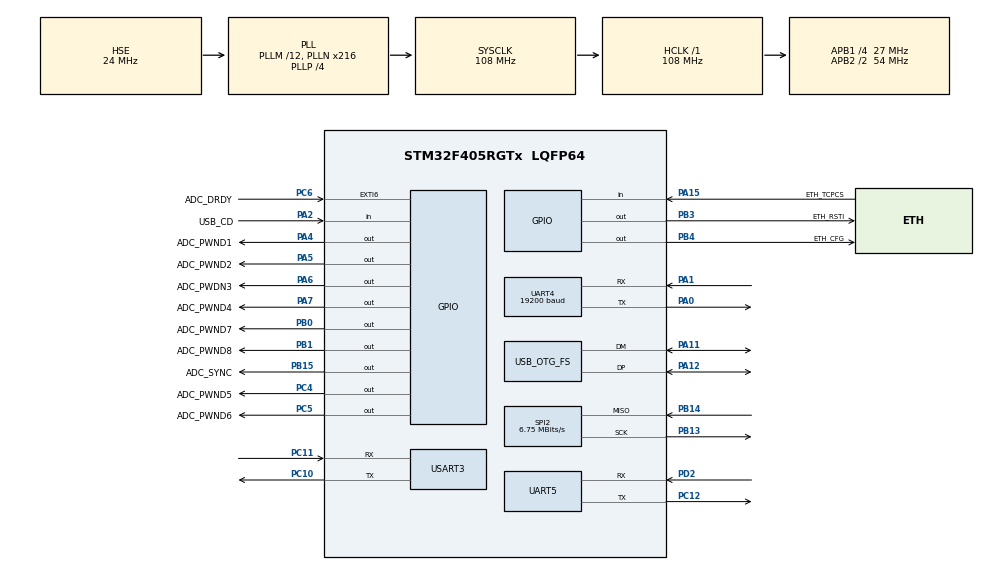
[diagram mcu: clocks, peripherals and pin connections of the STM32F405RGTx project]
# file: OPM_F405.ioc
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Dma.Request0=UART4_RX
Dma.Request1=UART4_TX
Dma.Request2=SPI2_RX
Dma.Request3=USART3_RX
Dma.Request4=UART5_RX
Dma.SPI2_RX.2.Direction=DMA_PERIPH_TO_MEMORY
Dma.SPI2_RX.2.FIFOMode=DMA_FIFOMODE_DISABLE
Dma.SPI2_RX.2.Instance=DMA1_Stream3
Dma.SPI2_RX.2.MemDataAlignment=DMA_MDATAALIGN_BYTE
Dma.SPI2_RX.2.MemInc=DMA_MINC_ENABLE
Dma.SPI2_RX.2.Mode=DMA_NORMAL
Dma.SPI2_RX.2.PeriphDataAlignment=DMA_PDATAALIGN_BYTE
Dma.SPI2_RX.2.PeriphInc=DMA_PINC_DISABLE
Dma.SPI2_RX.2.Priority=DMA_PRIORITY_LOW
Dma.UART4_RX.0.Direction=DMA_PERIPH_TO_MEMORY
Dma.UART4_RX.0.FIFOMode=DMA_FIFOMODE_DISABLE
Dma.UART4_RX.0.Instance=DMA1_Stream2
Dma.UART4_RX.0.MemDataAlignment=DMA_MDATAALIGN_BYTE
Dma.UART4_RX.0.MemInc=DMA_MINC_ENABLE
Dma.UART4_RX.0.Mode=DMA_NORMAL
Dma.UART4_RX.0.PeriphDataAlignment=DMA_PDATAALIGN_BYTE
Dma.UART4_RX.0.PeriphInc=DMA_PINC_DISABLE
Dma.UART4_RX.0.Priority=DMA_PRIORITY_LOW
Dma.UART4_TX.1.Direction=DMA_MEMORY_TO_PERIPH
Dma.UART4_TX.1.FIFOMode=DMA_FIFOMODE_DISABLE
Dma.UART4_TX.1.Instance=DMA1_Stream4
Dma.UART4_TX.1.MemDataAlignment=DMA_MDATAALIGN_BYTE
Dma.UART4_TX.1.MemInc=DMA_MINC_ENABLE
Dma.UART4_TX.1.Mode=DMA_NORMAL
Dma.UART4_TX.1.PeriphDataAlignment=DMA_PDATAALIGN_BYTE
Dma.UART4_TX.1.PeriphInc=DMA_PINC_DISABLE
Dma.UART4_TX.1.Priority=DMA_PRIORITY_LOW
Dma.UART5_RX.4.Direction=DMA_PERIPH_TO_MEMORY
Dma.UART5_RX.4.FIFOMode=DMA_FIFOMODE_DISABLE
Dma.UART5_RX.4.Instance=DMA1_Stream0
Dma.UART5_RX.4.MemDataAlignment=DMA_MDATAALIGN_BYTE
Dma.UART5_RX.4.MemInc=DMA_MINC_ENABLE
Dma.UART5_RX.4.Mode=DMA_NORMAL
Dma.UART5_RX.4.PeriphDataAlignment=DMA_PDATAALIGN_BYTE
Dma.UART5_RX.4.PeriphInc=DMA_PINC_DISABLE
Dma.UART5_RX.4.Priority=DMA_PRIORITY_LOW
Dma.USART3_RX.3.Direction=DMA_PERIPH_TO_MEMORY
Dma.USART3_RX.3.FIFOMode=DMA_FIFOMODE_DISABLE
Dma.USART3_RX.3.Instance=DMA1_Stream1
Dma.USART3_RX.3.MemDataAlignment=DMA_MDATAALIGN_BYTE
Dma.USART3_RX.3.MemInc=DMA_MINC_ENABLE
Dma.USART3_RX.3.Mode=DMA_NORMAL
Dma.USART3_RX.3.PeriphDataAlignment=DMA_PDATAALIGN_BYTE
Dma.USART3_RX.3.PeriphInc=DMA_PINC_DISABLE
Dma.USART3_RX.3.Priority=DMA_PRIORITY_LOW
FREERTOS.Tasks01=defaultTask,24,128,StartDefaultTask,Default,NULL,Dynamic,NULL,NULL
Mcu.Family=STM32F4
Mcu.Name=STM32F405RGTx
Mcu.Package=LQFP64
NVIC.DMA1_Stream0_IRQn=true\:5\:0\:false\:false\:true\:true\:false\:true\:true
NVIC.DMA1_Stream1_IRQn=true\:5\:0\:false\:false\:true\:true\:false\:true\:true
NVIC.DMA1_Stream2_IRQn=true\:5\:0\:false\:false\:true\:true\:false\:true\:true
NVIC.DMA1_Stream3_IRQn=true\:5\:0\:false\:false\:true\:true\:false\:true\:true
NVIC.DMA1_Stream4_IRQn=true\:5\:0\:false\:false\:true\:true\:false\:true\:true
NVIC.EXTI9_5_IRQn=true\:5\:0\:false\:false\:true\:true\:true\:true\:true
NVIC.PriorityGroup=NVIC_PRIORITYGROUP_4
NVIC.TIM1_UP_TIM10_IRQn=true\:15\:0\:false\:false\:true\:false\:false\:true\:true
NVIC.TIM8_TRG_COM_TIM14_IRQn=true\:5\:0\:false\:false\:true\:true\:true\:false\:true
NVIC.TimeBase=TIM1_UP_TIM10_IRQn
NVIC.TimeBaseIP=TIM1
NVIC.UART4_IRQn=true\:5\:0\:false\:false\:true\:true\:true\:true\:true
NVIC.UART5_IRQn=true\:5\:0\:false\:false\:true\:true\:true\:true\:true
NVIC.USART3_IRQn=true\:5\:0\:false\:false\:true\:true\:true\:true\:true
PA0-WKUP.Mode=Asynchronous
PA0-WKUP.Signal=UART4_TX
PA1.Mode=Asynchronous
PA1.Signal=UART4_RX
PA11.Mode=Device_Only
PA11.Signal=USB_OTG_FS_DM
PA12.Mode=Device_Only
PA12.Signal=USB_OTG_FS_DP
PA13.Mode=Serial_Wire
PA13.Signal=SYS_JTMS-SWDIO
PA14.Mode=Serial_Wire
PA14.Signal=SYS_JTCK-SWCLK
PA15.GPIO_Label=ETH_TCPCS
PA15.Signal=GPIO_Input
PA2.GPIO_Label=USB_CD
PA2.Signal=GPIO_Input
PA4.GPIO_Label=ADC_PWND1
PA4.Signal=GPIO_Output
PA5.GPIO_Label=ADC_PWND2
PA5.Signal=GPIO_Output
PA6.GPIO_Label=ADC_PWDN3
PA6.Signal=GPIO_Output
PA7.GPIO_Label=ADC_PWND4
PA7.Signal=GPIO_Output
PB0.GPIO_Label=ADC_PWND7
PB0.Signal=GPIO_Output
PB1.GPIO_Label=ADC_PWND8
PB1.Signal=GPIO_Output
PB13.Mode=RX_Only_Simplex_Unidirect_Master
PB13.Signal=SPI2_SCK
PB14.Mode=RX_Only_Simplex_Unidirect_Master
PB14.Signal=SPI2_MISO
PB15.GPIO_Label=ADC_SYNC
PB15.Signal=GPIO_Output
PB3.GPIO_Label=ETH_RSTI
PB3.Signal=GPIO_Output
PB4.GPIO_Label=ETH_CFG
PB4.Signal=GPIO_Output
PC10.Mode=Asynchronous
PC10.Signal=USART3_TX
PC11.Mode=Asynchronous
PC11.Signal=USART3_RX
PC12.Mode=Asynchronous
PC12.Signal=UART5_TX
PC4.GPIO_Label=ADC_PWND5
PC4.Signal=GPIO_Output
PC5.GPIO_Label=ADC_PWND6
PC5.Signal=GPIO_Output
PC6.GPIO_Label=ADC_DRDY
PC6.GPIO_ModeDefaultEXTI=GPIO_MODE_IT_FALLING
PC6.GPIO_PuPd=GPIO_NOPULL
PC6.Signal=GPXTI6
PD2.Mode=Asynchronous
PD2.Signal=UART5_RX
PH0-OSC_IN.Mode=HSE-External-Clock-Source
PH0-OSC_IN.Signal=RCC_OSC_IN
PH1-OSC_OUT.Mode=HSE-External-Clock-Source
PH1-OSC_OUT.Signal=RCC_OSC_OUT
ProjectManager.HeapSize=0x200
ProjectManager.StackSize=0x400
ProjectManager.TargetToolchain=MDK-ARM V5.32
RCC.48MHZClocksFreq_Value=48000000
RCC.AHBFreq_Value=108000000
RCC.APB1CLKDivider=RCC_HCLK_DIV4
RCC.APB1Freq_Value=27000000
RCC.APB1TimFreq_Value=54000000
RCC.APB2CLKDivider=RCC_HCLK_DIV2
RCC.APB2Freq_Value=54000000
RCC.APB2TimFreq_Value=108000000
RCC.CortexFreq_Value=108000000
RCC.HCLKFreq_Value=108000000
RCC.HSE_VALUE=24000000
RCC.HSI_VALUE=16000000
RCC.LSE_VALUE=32768
RCC.PLLM=12
RCC.PLLN=216
RCC.PLLP=RCC_PLLP_DIV4
RCC.PLLQ=9
RCC.SYSCLKFreq_VALUE=108000000
RCC.SYSCLKSource=RCC_SYSCLKSOURCE_PLLCLK
RCC.VCOOutputFreq_Value=432000000
SPI2.BaudRatePrescaler=SPI_BAUDRATEPRESCALER_4
SPI2.CalculateBaudRate=6.75 MBits/s
SPI2.Direction=SPI_DIRECTION_2LINES_RXONLY
SPI2.Mode=SPI_MODE_MASTER
SPI2.VirtualType=VM_MASTER
TIM14.AutoReloadPreload=TIM_AUTORELOAD_PRELOAD_ENABLE
TIM14.Channel=TIM_CHANNEL_1
TIM14.Period=3000-1
TIM14.Prescaler=72-1
TIM2.TIM_MasterSlaveMode=TIM_MASTERSLAVEMODE_DISABLE
UART4.BaudRate=19200
UART4.VirtualMode=Asynchronous
UART5.VirtualMode=Asynchronous
USART3.VirtualMode=VM_ASYNC
USB_OTG_FS.VirtualMode=Device_Only
VP_FREERTOS_VS_CMSIS_V2.Mode=CMSIS_V2
VP_SYS_VS_tim1.Mode=TIM1
VP_TIM14_VS_ClockSourceINT.Mode=Enable_Timer
VP_TIM14_VS_no_output1.Mode=PWM Generation1 No Output
VP_TIM2_VS_ClockSourceINT.Mode=Internal
board=custom

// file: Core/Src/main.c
/* USER CODE BEGIN Header */
/**
  ******************************************************************************
  * @file           : main.c
  * @brief          : Main program body
  ******************************************************************************
  * @attention
  *
  * Copyright (c) 2026 STMicroelectronics.
  * All rights reserved.
  *
  * This software is licensed under terms that can be found in the LICENSE file
  * in the root directory of this software component.
  * If no LICENSE file comes with this software, it is provided AS-IS.
  *
  ******************************************************************************
  */
/* USER CODE END Header */
#include "main.h"
#include "cmsis_os.h"

/* USER CODE BEGIN Includes */
#include "ADC_Task.h"
#include "UART_Task.h"

/* USER CODE END Includes */

SPI_HandleTypeDef hspi2;
DMA_HandleTypeDef hdma_spi2_rx;

TIM_HandleTypeDef htim2;
TIM_HandleTypeDef htim14;

UART_HandleTypeDef huart4;
UART_HandleTypeDef huart5;
UART_HandleTypeDef huart3;
DMA_HandleTypeDef hdma_uart4_rx;
DMA_HandleTypeDef hdma_uart4_tx;
DMA_HandleTypeDef hdma_uart5_rx;
DMA_HandleTypeDef hdma_usart3_rx;

PCD_HandleTypeDef hpcd_USB_OTG_FS;

/* Definitions for defaultTask */
osThreadId_t defaultTaskHandle;
const osThreadAttr_t defaultTask_attributes = {
  .name = "defaultTask",
  .stack_size = 128 * 4,
  .priority = (osPriority_t) osPriorityNormal,
};

void SystemClock_Config(void);
static void MX_GPIO_Init(void);
static void MX_DMA_Init(void);
static void MX_SPI2_Init(void);
static void MX_UART4_Init(void);
static void MX_UART5_Init(void);
static void MX_USART3_UART_Init(void);
static void MX_USB_OTG_FS_PCD_Init(void);
static void MX_TIM14_Init(void);
static void MX_TIM2_Init(void);
void StartDefaultTask(void *argument);

int main(void)
{

  /* MCU Configuration--------------------------------------------------------*/

  /* Reset of all peripherals, Initializes the Flash interface and the Systick. */
  HAL_Init();

  /* Configure the system clock */
  SystemClock_Config();

  /* Initialize all configured peripherals */
  MX_GPIO_Init();
  MX_DMA_Init();
  MX_SPI2_Init();
  MX_UART4_Init();
  MX_UART5_Init();
  MX_USART3_UART_Init();
  MX_USB_OTG_FS_PCD_Init();
  MX_TIM14_Init();
  MX_TIM2_Init();

  /* Init scheduler */
  osKernelInitialize();

  /* Create the thread(s) */
  /* creation of defaultTask */
  defaultTaskHandle = osThreadNew(StartDefaultTask, NULL, &defaultTask_attributes);

  /* USER CODE BEGIN RTOS_THREADS */
  /* add threads, ... */
	adc_task_init();
	hmi_task_init();
	opm_task_init();
  /* USER CODE END RTOS_THREADS */

  /* Start scheduler */
  osKernelStart();

  /* We should never get here as control is now taken by the scheduler */

  /* Infinite loop */
  while (1)
  {

  }
}

void SystemClock_Config(void)
{
  RCC_OscInitTypeDef RCC_OscInitStruct = {0};
  RCC_ClkInitTypeDef RCC_ClkInitStruct = {0};

  /** Configure the main internal regulator output voltage
  */
  __HAL_RCC_PWR_CLK_ENABLE();
  __HAL_PWR_VOLTAGESCALING_CONFIG(PWR_REGULATOR_VOLTAGE_SCALE1);

  /** Initializes the RCC Oscillators according to the specified parameters
  * in the RCC_OscInitTypeDef structure.
  */
  RCC_OscInitStruct.OscillatorType = RCC_OSCILLATORTYPE_HSE;
  RCC_OscInitStruct.HSEState = RCC_HSE_BYPASS;
  RCC_OscInitStruct.PLL.PLLState = RCC_PLL_ON;
  RCC_OscInitStruct.PLL.PLLSource = RCC_PLLSOURCE_HSE;
  RCC_OscInitStruct.PLL.PLLM = 12;
  RCC_OscInitStruct.PLL.PLLN = 216;
  RCC_OscInitStruct.PLL.PLLP = RCC_PLLP_DIV4;
  RCC_OscInitStruct.PLL.PLLQ = 9;
  if (HAL_RCC_OscConfig(&RCC_OscInitStruct) != HAL_OK)
  {
    Error_Handler();
  }

  /** Initializes the CPU, AHB and APB buses clocks
  */
  RCC_ClkInitStruct.ClockType = RCC_CLOCKTYPE_HCLK|RCC_CLOCKTYPE_SYSCLK
                              |RCC_CLOCKTYPE_PCLK1|RCC_CLOCKTYPE_PCLK2;
  RCC_ClkInitStruct.SYSCLKSource = RCC_SYSCLKSOURCE_PLLCLK;
  RCC_ClkInitStruct.AHBCLKDivider = RCC_SYSCLK_DIV1;
  RCC_ClkInitStruct.APB1CLKDivider = RCC_HCLK_DIV4;
  RCC_ClkInitStruct.APB2CLKDivider = RCC_HCLK_DIV2;

  if (HAL_RCC_ClockConfig(&RCC_ClkInitStruct, FLASH_LATENCY_3) != HAL_OK)
  {
    Error_Handler();
  }
}

static void MX_SPI2_Init(void)
{

  /* SPI2 parameter configuration*/
  hspi2.Instance = SPI2;
  hspi2.Init.Mode = SPI_MODE_MASTER;
  hspi2.Init.Direction = SPI_DIRECTION_2LINES_RXONLY;
  hspi2.Init.DataSize = SPI_DATASIZE_8BIT;
  hspi2.Init.CLKPolarity = SPI_POLARITY_LOW;
  hspi2.Init.CLKPhase = SPI_PHASE_1EDGE;
  hspi2.Init.NSS = SPI_NSS_SOFT;
  hspi2.Init.BaudRatePrescaler = SPI_BAUDRATEPRESCALER_4;
  hspi2.Init.FirstBit = SPI_FIRSTBIT_MSB;
  hspi2.Init.TIMode = SPI_TIMODE_DISABLE;
  hspi2.Init.CRCCalculation = SPI_CRCCALCULATION_DISABLE;
  hspi2.Init.CRCPolynomial = 10;
  if (HAL_SPI_Init(&hspi2) != HAL_OK)
  {
    Error_Handler();
  }

}

static void MX_TIM2_Init(void)
{

  TIM_ClockConfigTypeDef sClockSourceConfig = {0};
  TIM_MasterConfigTypeDef sMasterConfig = {0};

  htim2.Instance = TIM2;
  htim2.Init.Prescaler = 0;
  htim2.Init.CounterMode = TIM_COUNTERMODE_UP;
  htim2.Init.Period = 4294967295;
  htim2.Init.ClockDivision = TIM_CLOCKDIVISION_DIV1;
  htim2.Init.AutoReloadPreload = TIM_AUTORELOAD_PRELOAD_DISABLE;
  if (HAL_TIM_Base_Init(&htim2) != HAL_OK)
  {
    Error_Handler();
  }
  sClockSourceConfig.ClockSource = TIM_CLOCKSOURCE_INTERNAL;
  if (HAL_TIM_ConfigClockSource(&htim2, &sClockSourceConfig) != HAL_OK)
  {
    Error_Handler();
  }
  sMasterConfig.MasterOutputTrigger = TIM_TRGO_RESET;
  sMasterConfig.MasterSlaveMode = TIM_MASTERSLAVEMODE_DISABLE;
  if (HAL_TIMEx_MasterConfigSynchronization(&htim2, &sMasterConfig) != HAL_OK)
  {
    Error_Handler();
  }

}

static void MX_TIM14_Init(void)
{

  TIM_OC_InitTypeDef sConfigOC = {0};

  htim14.Instance = TIM14;
  htim14.Init.Prescaler = 72-1;
  htim14.Init.CounterMode = TIM_COUNTERMODE_UP;
  htim14.Init.Period = 3000-1;
  htim14.Init.ClockDivision = TIM_CLOCKDIVISION_DIV1;
  htim14.Init.AutoReloadPreload = TIM_AUTORELOAD_PRELOAD_ENABLE;
  if (HAL_TIM_Base_Init(&htim14) != HAL_OK)
  {
    Error_Handler();
  }
  if (HAL_TIM_PWM_Init(&htim14) != HAL_OK)
  {
    Error_Handler();
  }
  sConfigOC.OCMode = TIM_OCMODE_PWM1;
  sConfigOC.Pulse = 0;
  sConfigOC.OCPolarity = TIM_OCPOLARITY_HIGH;
  sConfigOC.OCFastMode = TIM_OCFAST_DISABLE;
  if (HAL_TIM_PWM_ConfigChannel(&htim14, &sConfigOC, TIM_CHANNEL_1) != HAL_OK)
  {
    Error_Handler();
  }

}

static void MX_UART4_Init(void)
{

  huart4.Instance = UART4;
  huart4.Init.BaudRate = 19200;
  huart4.Init.WordLength = UART_WORDLENGTH_8B;
  huart4.Init.StopBits = UART_STOPBITS_1;
  huart4.Init.Parity = UART_PARITY_NONE;
  huart4.Init.Mode = UART_MODE_TX_RX;
  huart4.Init.HwFlowCtl = UART_HWCONTROL_NONE;
  huart4.Init.OverSampling = UART_OVERSAMPLING_16;
  if (HAL_UART_Init(&huart4) != HAL_OK)
  {
    Error_Handler();
  }

}

static void MX_UART5_Init(void)
{

  huart5.Instance = UART5;
  huart5.Init.BaudRate = 115200;
  huart5.Init.WordLength = UART_WORDLENGTH_8B;
  huart5.Init.StopBits = UART_STOPBITS_1;
  huart5.Init.Parity = UART_PARITY_NONE;
  huart5.Init.Mode = UART_MODE_TX_RX;
  huart5.Init.HwFlowCtl = UART_HWCONTROL_NONE;
  huart5.Init.OverSampling = UART_OVERSAMPLING_16;
  if (HAL_UART_Init(&huart5) != HAL_OK)
  {
    Error_Handler();
  }

}

static void MX_USART3_UART_Init(void)
{

  huart3.Instance = USART3;
  huart3.Init.BaudRate = 115200;
  huart3.Init.WordLength = UART_WORDLENGTH_8B;
  huart3.Init.StopBits = UART_STOPBITS_1;
  huart3.Init.Parity = UART_PARITY_NONE;
  huart3.Init.Mode = UART_MODE_TX_RX;
  huart3.Init.HwFlowCtl = UART_HWCONTROL_NONE;
  huart3.Init.OverSampling = UART_OVERSAMPLING_16;
  if (HAL_UART_Init(&huart3) != HAL_OK)
  {
    Error_Handler();
  }

}

static void MX_USB_OTG_FS_PCD_Init(void)
{

  hpcd_USB_OTG_FS.Instance = USB_OTG_FS;
  hpcd_USB_OTG_FS.Init.dev_endpoints = 4;
  hpcd_USB_OTG_FS.Init.speed = PCD_SPEED_FULL;
  hpcd_USB_OTG_FS.Init.dma_enable = DISABLE;
  hpcd_USB_OTG_FS.Init.phy_itface = PCD_PHY_EMBEDDED;
  hpcd_USB_OTG_FS.Init.Sof_enable = DISABLE;
  hpcd_USB_OTG_FS.Init.low_power_enable = DISABLE;
  hpcd_USB_OTG_FS.Init.lpm_enable = DISABLE;
  hpcd_USB_OTG_FS.Init.vbus_sensing_enable = DISABLE;
  hpcd_USB_OTG_FS.Init.use_dedicated_ep1 = DISABLE;
  if (HAL_PCD_Init(&hpcd_USB_OTG_FS) != HAL_OK)
  {
    Error_Handler();
  }

}

static void MX_DMA_Init(void)
{

  /* DMA controller clock enable */
  __HAL_RCC_DMA1_CLK_ENABLE();

  /* DMA interrupt init */
  /* DMA1_Stream0_IRQn interrupt configuration */
  HAL_NVIC_SetPriority(DMA1_Stream0_IRQn, 5, 0);
  HAL_NVIC_EnableIRQ(DMA1_Stream0_IRQn);
  /* DMA1_Stream1_IRQn interrupt configuration */
  HAL_NVIC_SetPriority(DMA1_Stream1_IRQn, 5, 0);
  HAL_NVIC_EnableIRQ(DMA1_Stream1_IRQn);
  /* DMA1_Stream2_IRQn interrupt configuration */
  HAL_NVIC_SetPriority(DMA1_Stream2_IRQn, 5, 0);
  HAL_NVIC_EnableIRQ(DMA1_Stream2_IRQn);
  /* DMA1_Stream3_IRQn interrupt configuration */
  HAL_NVIC_SetPriority(DMA1_Stream3_IRQn, 5, 0);
  HAL_NVIC_EnableIRQ(DMA1_Stream3_IRQn);
  /* DMA1_Stream4_IRQn interrupt configuration */
  HAL_NVIC_SetPriority(DMA1_Stream4_IRQn, 5, 0);
  HAL_NVIC_EnableIRQ(DMA1_Stream4_IRQn);

}

static void MX_GPIO_Init(void)
{
  GPIO_InitTypeDef GPIO_InitStruct = {0};

  /* GPIO Ports Clock Enable */
  __HAL_RCC_GPIOH_CLK_ENABLE();
  __HAL_RCC_GPIOA_CLK_ENABLE();
  __HAL_RCC_GPIOC_CLK_ENABLE();
  __HAL_RCC_GPIOB_CLK_ENABLE();
  __HAL_RCC_GPIOD_CLK_ENABLE();

  /*Configure GPIO pin Output Level */
  HAL_GPIO_WritePin(GPIOA, ADC_PWND1_Pin|ADC_PWND2_Pin|ADC_PWDN3_Pin|ADC_PWND4_Pin, GPIO_PIN_RESET);

  /*Configure GPIO pin Output Level */
  HAL_GPIO_WritePin(GPIOC, ADC_PWND5_Pin|ADC_PWND6_Pin, GPIO_PIN_RESET);

  /*Configure GPIO pin Output Level */
  HAL_GPIO_WritePin(GPIOB, ADC_PWND7_Pin|ADC_PWND8_Pin|ADC_SYNC_Pin|ETH_RSTI_Pin
                          |ETH_CFG_Pin, GPIO_PIN_RESET);

  /*Configure GPIO pins : USB_CD_Pin ETH_TCPCS_Pin */
  GPIO_InitStruct.Pin = USB_CD_Pin|ETH_TCPCS_Pin;
  GPIO_InitStruct.Mode = GPIO_MODE_INPUT;
  GPIO_InitStruct.Pull = GPIO_NOPULL;
  HAL_GPIO_Init(GPIOA, &GPIO_InitStruct);

  /*Configure GPIO pins : ADC_PWND1_Pin ADC_PWND2_Pin ADC_PWDN3_Pin ADC_PWND4_Pin */
  GPIO_InitStruct.Pin = ADC_PWND1_Pin|ADC_PWND2_Pin|ADC_PWDN3_Pin|ADC_PWND4_Pin;
  GPIO_InitStruct.Mode = GPIO_MODE_OUTPUT_PP;
  GPIO_InitStruct.Pull = GPIO_NOPULL;
  GPIO_InitStruct.Speed = GPIO_SPEED_FREQ_LOW;
  HAL_GPIO_Init(GPIOA, &GPIO_InitStruct);

  /*Configure GPIO pins : ADC_PWND5_Pin ADC_PWND6_Pin */
  GPIO_InitStruct.Pin = ADC_PWND5_Pin|ADC_PWND6_Pin;
  GPIO_InitStruct.Mode = GPIO_MODE_OUTPUT_PP;
  GPIO_InitStruct.Pull = GPIO_NOPULL;
  GPIO_InitStruct.Speed = GPIO_SPEED_FREQ_LOW;
  HAL_GPIO_Init(GPIOC, &GPIO_InitStruct);

  /*Configure GPIO pins : ADC_PWND7_Pin ADC_PWND8_Pin ADC_SYNC_Pin ETH_RSTI_Pin
                           ETH_CFG_Pin */
  GPIO_InitStruct.Pin = ADC_PWND7_Pin|ADC_PWND8_Pin|ADC_SYNC_Pin|ETH_RSTI_Pin
                          |ETH_CFG_Pin;
  GPIO_InitStruct.Mode = GPIO_MODE_OUTPUT_PP;
  GPIO_InitStruct.Pull = GPIO_NOPULL;
  GPIO_InitStruct.Speed = GPIO_SPEED_FREQ_LOW;
  HAL_GPIO_Init(GPIOB, &GPIO_InitStruct);

  /*Configure GPIO pin : ADC_DRDY_Pin */
  GPIO_InitStruct.Pin = ADC_DRDY_Pin;
  GPIO_InitStruct.Mode = GPIO_MODE_IT_FALLING;
  GPIO_InitStruct.Pull = GPIO_NOPULL;
  HAL_GPIO_Init(ADC_DRDY_GPIO_Port, &GPIO_InitStruct);

  /* EXTI interrupt init*/
  HAL_NVIC_SetPriority(EXTI9_5_IRQn, 5, 0);
  HAL_NVIC_EnableIRQ(EXTI9_5_IRQn);

}

void StartDefaultTask(void *argument)
{
  for(;;)
  {
    osDelay(1);
  }
}

void HAL_TIM_PeriodElapsedCallback(TIM_HandleTypeDef *htim)
{
  if (htim->Instance == TIM1)
  {
    HAL_IncTick();
  }
}

void Error_Handler(void)
{
  __disable_irq();
  while (1)
  {
  }
}
